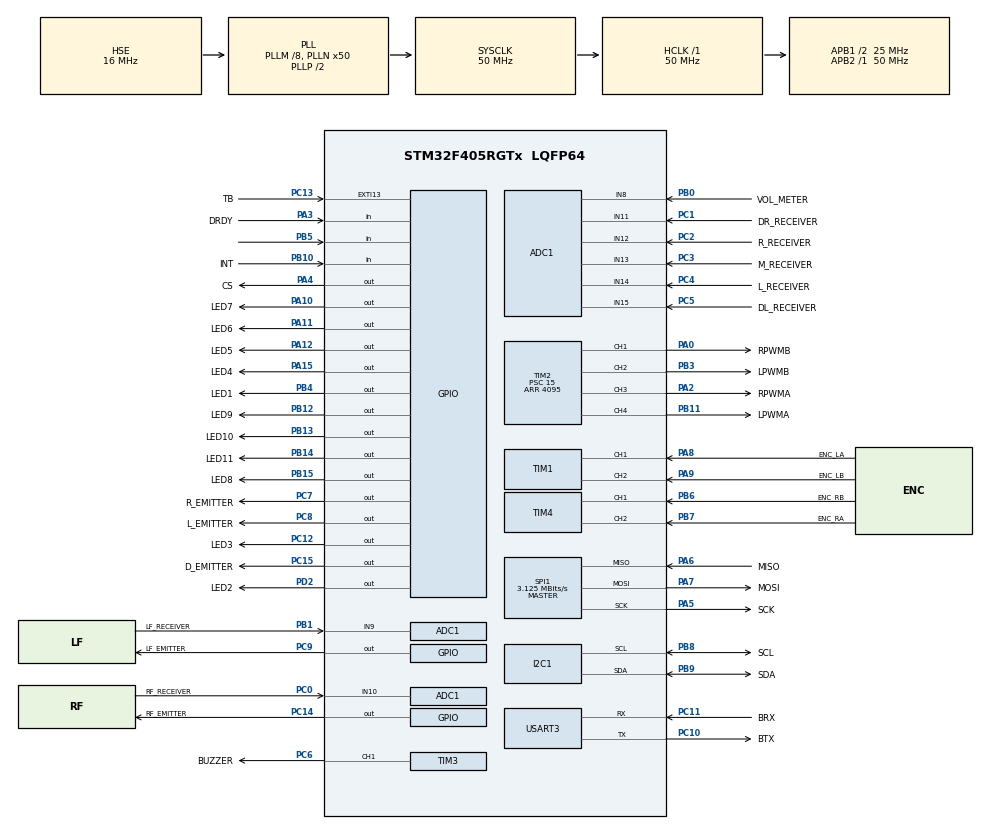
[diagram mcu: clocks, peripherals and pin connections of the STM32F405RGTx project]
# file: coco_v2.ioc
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ADC1.Channel-1\#ChannelRegularConversion=ADC_CHANNEL_10
ADC1.NbrOfConversionFlag=1
ADC1.Rank-1\#ChannelRegularConversion=1
ADC1.SamplingTime-1\#ChannelRegularConversion=ADC_SAMPLETIME_3CYCLES
ADC1.master=1
Dma.ADC1.0.Direction=DMA_PERIPH_TO_MEMORY
Dma.ADC1.0.FIFOMode=DMA_FIFOMODE_DISABLE
Dma.ADC1.0.Instance=DMA2_Stream0
Dma.ADC1.0.MemDataAlignment=DMA_MDATAALIGN_HALFWORD
Dma.ADC1.0.MemInc=DMA_MINC_ENABLE
Dma.ADC1.0.Mode=DMA_NORMAL
Dma.ADC1.0.PeriphDataAlignment=DMA_PDATAALIGN_HALFWORD
Dma.ADC1.0.PeriphInc=DMA_PINC_DISABLE
Dma.ADC1.0.Priority=DMA_PRIORITY_LOW
Dma.Request0=ADC1
I2C1.I2C_Mode=I2C_Fast
Mcu.Family=STM32F4
Mcu.Name=STM32F405RGTx
Mcu.Package=LQFP64
NVIC.DMA2_Stream0_IRQn=true\:0\:0\:false\:false\:true\:false\:true\:true
NVIC.EXTI15_10_IRQn=true\:0\:0\:false\:false\:true\:true\:true\:true
NVIC.PriorityGroup=NVIC_PRIORITYGROUP_4
NVIC.TIM8_UP_TIM13_IRQn=true\:0\:0\:false\:false\:true\:true\:true\:true
PA0-WKUP.GPIO_Label=RPWMB
PA0-WKUP.Signal=S_TIM2_CH1_ETR
PA10.GPIO_Label=LED7
PA10.GPIO_PuPd=GPIO_PULLDOWN
PA10.Signal=GPIO_Output
PA11.GPIO_Label=LED6
PA11.GPIO_PuPd=GPIO_PULLDOWN
PA11.Signal=GPIO_Output
PA12.GPIO_Label=LED5
PA12.GPIO_PuPd=GPIO_PULLDOWN
PA12.Signal=GPIO_Output
PA13.GPIO_Label=JTMS
PA13.Mode=Serial_Wire
PA13.Signal=SYS_JTMS-SWDIO
PA14.GPIO_Label=JTCK
PA14.Mode=Serial_Wire
PA14.Signal=SYS_JTCK-SWCLK
PA15.GPIO_Label=LED4
PA15.GPIO_PuPd=GPIO_PULLDOWN
PA15.Signal=GPIO_Output
PA2.GPIO_Label=RPWMA
PA2.Signal=S_TIM2_CH3
PA3.GPIO_Label=DRDY
PA3.Signal=GPIO_Input
PA4.GPIO_Label=CS
PA4.Signal=GPIO_Output
PA5.GPIO_Label=SCK
PA5.Mode=Full_Duplex_Master
PA5.Signal=SPI1_SCK
PA6.GPIO_Label=MISO
PA6.Mode=Full_Duplex_Master
PA6.Signal=SPI1_MISO
PA7.GPIO_Label=MOSI
PA7.Mode=Full_Duplex_Master
PA7.Signal=SPI1_MOSI
PA8.GPIO_Label=ENC_LA
PA8.Signal=S_TIM1_CH1
PA9.GPIO_Label=ENC_LB
PA9.Signal=S_TIM1_CH2
PB0.GPIO_Label=VOL_METER
PB0.Signal=ADCx_IN8
PB1.GPIO_Label=LF_RECEIVER
PB1.Signal=ADCx_IN9
PB10.GPIO_Label=INT
PB10.Signal=GPIO_Input
PB11.GPIO_Label=LPWMA
PB11.Signal=S_TIM2_CH4
PB12.GPIO_Label=LED9
PB12.GPIO_PuPd=GPIO_PULLDOWN
PB12.Signal=GPIO_Output
PB13.GPIO_Label=LED10
PB13.GPIO_PuPd=GPIO_PULLDOWN
PB13.Signal=GPIO_Output
PB14.GPIO_Label=LED11
PB14.GPIO_PuPd=GPIO_PULLDOWN
PB14.Signal=GPIO_Output
PB15.GPIO_Label=LED8
PB15.GPIO_ModeDefaultOutputPP=GPIO_MODE_OUTPUT_PP
PB15.GPIO_PuPd=GPIO_PULLDOWN
PB15.Signal=GPIO_Output
PB3.GPIO_Label=LPWMB
PB3.Signal=S_TIM2_CH2
PB4.GPIO_Label=LED1
PB4.GPIO_PuPd=GPIO_PULLDOWN
PB4.Signal=GPIO_Output
PB5.Signal=GPIO_Input
PB6.GPIO_Label=ENC_RB
PB6.Signal=S_TIM4_CH1
PB7.GPIO_Label=ENC_RA
PB7.Signal=S_TIM4_CH2
PB8.GPIO_Label=SCL
PB8.Mode=I2C
PB8.Signal=I2C1_SCL
PB9.GPIO_Label=SDA
PB9.Mode=I2C
PB9.Signal=I2C1_SDA
PC0.GPIO_Label=RF_RECEIVER
PC0.Signal=ADCx_IN10
PC1.GPIO_Label=DR_RECEIVER
PC1.Signal=ADCx_IN11
PC10.GPIO_Label=BTX
PC10.Mode=Asynchronous
PC10.Signal=USART3_TX
PC11.GPIO_Label=BRX
PC11.Mode=Asynchronous
PC11.Signal=USART3_RX
PC12.GPIO_Label=LED3
PC12.GPIO_PuPd=GPIO_PULLDOWN
PC12.Signal=GPIO_Output
PC13-ANTI_TAMP.GPIO_Label=TB
PC13-ANTI_TAMP.GPIO_PuPd=GPIO_PULLDOWN
PC13-ANTI_TAMP.Signal=GPXTI13
PC14-OSC32_IN.GPIO_Label=RF_EMITTER
PC14-OSC32_IN.Signal=GPIO_Output
PC15-OSC32_OUT.GPIO_Label=D_EMITTER
PC15-OSC32_OUT.Signal=GPIO_Output
PC2.GPIO_Label=R_RECEIVER
PC2.Signal=ADCx_IN12
PC3.GPIO_Label=M_RECEIVER
PC3.Signal=ADCx_IN13
PC4.GPIO_Label=L_RECEIVER
PC4.Signal=ADCx_IN14
PC5.GPIO_Label=DL_RECEIVER
PC5.Signal=ADCx_IN15
PC6.GPIO_Label=BUZZER
PC6.Signal=S_TIM3_CH1
PC7.GPIO_Label=R_EMITTER
PC7.Signal=GPIO_Output
PC8.GPIO_Label=L_EMITTER
PC8.Signal=GPIO_Output
PC9.GPIO_Label=LF_EMITTER
PC9.Signal=GPIO_Output
PD2.GPIO_Label=LED2
PD2.GPIO_PuPd=GPIO_PULLDOWN
PD2.Signal=GPIO_Output
PH0-OSC_IN.Mode=HSE-External-Oscillator
PH0-OSC_IN.Signal=RCC_OSC_IN
PH1-OSC_OUT.Mode=HSE-External-Oscillator
PH1-OSC_OUT.Signal=RCC_OSC_OUT
ProjectManager.HeapSize=0x200
ProjectManager.StackSize=0x400
ProjectManager.TargetToolchain=STM32CubeIDE
RCC.48MHZClocksFreq_Value=25000000
RCC.AHBFreq_Value=50000000
RCC.APB1CLKDivider=RCC_HCLK_DIV2
RCC.APB1Freq_Value=25000000
RCC.APB1TimFreq_Value=50000000
RCC.APB2Freq_Value=50000000
RCC.APB2TimFreq_Value=50000000
RCC.CortexFreq_Value=50000000
RCC.HCLKFreq_Value=50000000
RCC.HSE_VALUE=16000000
RCC.HSI_VALUE=16000000
RCC.LSE_VALUE=32768
RCC.PLLM=8
RCC.PLLN=50
RCC.PLLSourceVirtual=RCC_PLLSOURCE_HSE
RCC.SYSCLKFreq_VALUE=50000000
RCC.SYSCLKSource=RCC_SYSCLKSOURCE_PLLCLK
RCC.VCOOutputFreq_Value=100000000
SH.ADCx_IN10.0=ADC1_IN10,IN10
SH.ADCx_IN11.0=ADC1_IN11,IN11
SH.ADCx_IN12.0=ADC1_IN12,IN12
SH.ADCx_IN13.0=ADC1_IN13,IN13
SH.ADCx_IN14.0=ADC1_IN14,IN14
SH.ADCx_IN15.0=ADC1_IN15,IN15
SH.ADCx_IN8.0=ADC1_IN8,IN8
SH.ADCx_IN9.0=ADC1_IN9,IN9
SH.S_TIM1_CH1.0=TIM1_CH1,Encoder_Interface
SH.S_TIM1_CH2.0=TIM1_CH2,Encoder_Interface
SH.S_TIM2_CH1_ETR.0=TIM2_CH1,PWM Generation1 CH1
SH.S_TIM2_CH2.0=TIM2_CH2,PWM Generation2 CH2
SH.S_TIM2_CH3.0=TIM2_CH3,PWM Generation3 CH3
SH.S_TIM2_CH4.0=TIM2_CH4,PWM Generation4 CH4
SH.S_TIM3_CH1.0=TIM3_CH1,PWM Generation1 CH1
SH.S_TIM4_CH1.0=TIM4_CH1,Encoder_Interface
SH.S_TIM4_CH2.0=TIM4_CH2,Encoder_Interface
SPI1.BaudRatePrescaler=SPI_BAUDRATEPRESCALER_16
SPI1.CalculateBaudRate=3.125 MBits/s
SPI1.Direction=SPI_DIRECTION_2LINES
SPI1.Mode=SPI_MODE_MASTER
SPI1.VirtualType=VM_MASTER
TIM1.AutoReloadPreload=TIM_AUTORELOAD_PRELOAD_ENABLE
TIM13.Period=50000
TIM13.Prescaler=0
TIM2.AutoReloadPreload=TIM_AUTORELOAD_PRELOAD_DISABLE
TIM2.Channel-PWM\ Generation1\ CH1=TIM_CHANNEL_1
TIM2.Channel-PWM\ Generation2\ CH2=TIM_CHANNEL_2
TIM2.Channel-PWM\ Generation3\ CH3=TIM_CHANNEL_3
TIM2.Channel-PWM\ Generation4\ CH4=TIM_CHANNEL_4
TIM2.Period=4095
TIM2.Prescaler=15
TIM3.Channel-PWM\ Generation1\ CH1=TIM_CHANNEL_1
TIM3.Period=1000
TIM3.Prescaler=18
TIM4.AutoReloadPreload=TIM_AUTORELOAD_PRELOAD_ENABLE
TIM4.EncoderMode=TIM_ENCODERMODE_TI2
TIM5.Period=0xffff-1
TIM5.Prescaler=49
USART3.VirtualMode=VM_ASYNC
VP_TIM13_VS_ClockSourceINT.Mode=Enable_Timer
VP_TIM2_VS_ClockSourceINT.Mode=Internal
VP_TIM3_VS_ClockSourceINT.Mode=Internal
VP_TIM5_VS_ClockSourceINT.Mode=Internal
board=custom

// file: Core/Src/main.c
/* USER CODE BEGIN Header */
/**
  ******************************************************************************
  * @file           : main.c
  * @brief          : Main program body
  ******************************************************************************
  * @attention
  *
  * Copyright (c) 2024 STMicroelectronics.
  * All rights reserved.
  *
  * This software is licensed under terms that can be found in the LICENSE file
  * in the root directory of this software component.
  * If no LICENSE file comes with this software, it is provided AS-IS.
  *
  ******************************************************************************
  */
/* USER CODE END Header */
#include "main.h"

/* USER CODE BEGIN Includes */
#include "main.h"
#define ITM_Port32(n) (*((volatile unsigned long *)(0xE0000000+4*n)))
/* USER CODE END Includes */

ADC_HandleTypeDef hadc1;
DMA_HandleTypeDef hdma_adc1;

I2C_HandleTypeDef hi2c1;

SPI_HandleTypeDef hspi1;

TIM_HandleTypeDef htim1;
TIM_HandleTypeDef htim2;
TIM_HandleTypeDef htim3;
TIM_HandleTypeDef htim4;
TIM_HandleTypeDef htim5;
TIM_HandleTypeDef htim13;

UART_HandleTypeDef huart3;

void SystemClock_Config(void);
static void MX_GPIO_Init(void);
static void MX_DMA_Init(void);
static void MX_SPI1_Init(void);
static void MX_ADC1_Init(void);
static void MX_I2C1_Init(void);
static void MX_TIM1_Init(void);
static void MX_TIM2_Init(void);
static void MX_TIM3_Init(void);
static void MX_TIM4_Init(void);
static void MX_USART3_UART_Init(void);
static void MX_TIM5_Init(void);
static void MX_TIM13_Init(void);

int main(void)
{

  /* MCU Configuration--------------------------------------------------------*/

  /* Reset of all peripherals, Initializes the Flash interface and the Systick. */

	HAL_Init();

  /* USER CODE BEGIN Init */
//  uint32_t left_pos;
//  uint32_t right_pos;
  /* USER CODE END Init */

  /* Configure the system clock */
  SystemClock_Config();

  /* USER CODE BEGIN SysInit */
  ITM_Port32(31) = 1;
  /* USER CODE END SysInit */

  /* Initialize all configured peripherals */
  MX_GPIO_Init();
  MX_DMA_Init();
  MX_SPI1_Init();
  MX_ADC1_Init();
  MX_I2C1_Init();
  MX_TIM1_Init();
  MX_TIM2_Init();
  MX_TIM3_Init();
  MX_TIM4_Init();
  MX_USART3_UART_Init();
  MX_TIM5_Init();
  MX_TIM13_Init();
  /* USER CODE BEGIN 2 */
  ITM_Port32(31) = 2;
  cppmain();
  /* USER CODE END 2 */

  /* Infinite loop */
  while (1)
  {

  }
}

void SystemClock_Config(void)
{
  RCC_OscInitTypeDef RCC_OscInitStruct = {0};
  RCC_ClkInitTypeDef RCC_ClkInitStruct = {0};

  /** Configure the main internal regulator output voltage
  */
  __HAL_RCC_PWR_CLK_ENABLE();
  __HAL_PWR_VOLTAGESCALING_CONFIG(PWR_REGULATOR_VOLTAGE_SCALE1);

  /** Initializes the RCC Oscillators according to the specified parameters
  * in the RCC_OscInitTypeDef structure.
  */
  RCC_OscInitStruct.OscillatorType = RCC_OSCILLATORTYPE_HSE;
  RCC_OscInitStruct.HSEState = RCC_HSE_ON;
  RCC_OscInitStruct.PLL.PLLState = RCC_PLL_ON;
  RCC_OscInitStruct.PLL.PLLSource = RCC_PLLSOURCE_HSE;
  RCC_OscInitStruct.PLL.PLLM = 8;
  RCC_OscInitStruct.PLL.PLLN = 50;
  RCC_OscInitStruct.PLL.PLLP = RCC_PLLP_DIV2;
  RCC_OscInitStruct.PLL.PLLQ = 4;
  if (HAL_RCC_OscConfig(&RCC_OscInitStruct) != HAL_OK)
  {
    Error_Handler();
  }

  /** Initializes the CPU, AHB and APB buses clocks
  */
  RCC_ClkInitStruct.ClockType = RCC_CLOCKTYPE_HCLK|RCC_CLOCKTYPE_SYSCLK
                              |RCC_CLOCKTYPE_PCLK1|RCC_CLOCKTYPE_PCLK2;
  RCC_ClkInitStruct.SYSCLKSource = RCC_SYSCLKSOURCE_PLLCLK;
  RCC_ClkInitStruct.AHBCLKDivider = RCC_SYSCLK_DIV1;
  RCC_ClkInitStruct.APB1CLKDivider = RCC_HCLK_DIV2;
  RCC_ClkInitStruct.APB2CLKDivider = RCC_HCLK_DIV1;

  if (HAL_RCC_ClockConfig(&RCC_ClkInitStruct, FLASH_LATENCY_1) != HAL_OK)
  {
    Error_Handler();
  }
}

static void MX_ADC1_Init(void)
{

  ADC_ChannelConfTypeDef sConfig = {0};

  /** Configure the global features of the ADC (Clock, Resolution, Data Alignment and number of conversion)
  */
  hadc1.Instance = ADC1;
  hadc1.Init.ClockPrescaler = ADC_CLOCK_SYNC_PCLK_DIV2;
  hadc1.Init.Resolution = ADC_RESOLUTION_12B;
  hadc1.Init.ScanConvMode = DISABLE;
  hadc1.Init.ContinuousConvMode = DISABLE;
  hadc1.Init.DiscontinuousConvMode = DISABLE;
  hadc1.Init.ExternalTrigConvEdge = ADC_EXTERNALTRIGCONVEDGE_NONE;
  hadc1.Init.ExternalTrigConv = ADC_SOFTWARE_START;
  hadc1.Init.DataAlign = ADC_DATAALIGN_RIGHT;
  hadc1.Init.NbrOfConversion = 1;
  hadc1.Init.DMAContinuousRequests = DISABLE;
  hadc1.Init.EOCSelection = ADC_EOC_SINGLE_CONV;
  if (HAL_ADC_Init(&hadc1) != HAL_OK)
  {
    Error_Handler();
  }

  /** Configure for the selected ADC regular channel its corresponding rank in the sequencer and its sample time.
  */
  sConfig.Channel = ADC_CHANNEL_10;
  sConfig.Rank = 1;
  sConfig.SamplingTime = ADC_SAMPLETIME_3CYCLES;
  if (HAL_ADC_ConfigChannel(&hadc1, &sConfig) != HAL_OK)
  {
    Error_Handler();
  }

}

static void MX_I2C1_Init(void)
{

  hi2c1.Instance = I2C1;
  hi2c1.Init.ClockSpeed = 400000;
  hi2c1.Init.DutyCycle = I2C_DUTYCYCLE_2;
  hi2c1.Init.OwnAddress1 = 0;
  hi2c1.Init.AddressingMode = I2C_ADDRESSINGMODE_7BIT;
  hi2c1.Init.DualAddressMode = I2C_DUALADDRESS_DISABLE;
  hi2c1.Init.OwnAddress2 = 0;
  hi2c1.Init.GeneralCallMode = I2C_GENERALCALL_DISABLE;
  hi2c1.Init.NoStretchMode = I2C_NOSTRETCH_DISABLE;
  if (HAL_I2C_Init(&hi2c1) != HAL_OK)
  {
    Error_Handler();
  }

}

static void MX_SPI1_Init(void)
{

  /* SPI1 parameter configuration*/
  hspi1.Instance = SPI1;
  hspi1.Init.Mode = SPI_MODE_MASTER;
  hspi1.Init.Direction = SPI_DIRECTION_2LINES;
  hspi1.Init.DataSize = SPI_DATASIZE_8BIT;
  hspi1.Init.CLKPolarity = SPI_POLARITY_LOW;
  hspi1.Init.CLKPhase = SPI_PHASE_1EDGE;
  hspi1.Init.NSS = SPI_NSS_SOFT;
  hspi1.Init.BaudRatePrescaler = SPI_BAUDRATEPRESCALER_16;
  hspi1.Init.FirstBit = SPI_FIRSTBIT_MSB;
  hspi1.Init.TIMode = SPI_TIMODE_DISABLE;
  hspi1.Init.CRCCalculation = SPI_CRCCALCULATION_DISABLE;
  hspi1.Init.CRCPolynomial = 10;
  if (HAL_SPI_Init(&hspi1) != HAL_OK)
  {
    Error_Handler();
  }

}

static void MX_TIM1_Init(void)
{

  TIM_Encoder_InitTypeDef sConfig = {0};
  TIM_MasterConfigTypeDef sMasterConfig = {0};

  htim1.Instance = TIM1;
  htim1.Init.Prescaler = 0;
  htim1.Init.CounterMode = TIM_COUNTERMODE_UP;
  htim1.Init.Period = 65535;
  htim1.Init.ClockDivision = TIM_CLOCKDIVISION_DIV1;
  htim1.Init.RepetitionCounter = 0;
  htim1.Init.AutoReloadPreload = TIM_AUTORELOAD_PRELOAD_ENABLE;
  sConfig.EncoderMode = TIM_ENCODERMODE_TI1;
  sConfig.IC1Polarity = TIM_ICPOLARITY_RISING;
  sConfig.IC1Selection = TIM_ICSELECTION_DIRECTTI;
  sConfig.IC1Prescaler = TIM_ICPSC_DIV1;
  sConfig.IC1Filter = 0;
  sConfig.IC2Polarity = TIM_ICPOLARITY_RISING;
  sConfig.IC2Selection = TIM_ICSELECTION_DIRECTTI;
  sConfig.IC2Prescaler = TIM_ICPSC_DIV1;
  sConfig.IC2Filter = 0;
  if (HAL_TIM_Encoder_Init(&htim1, &sConfig) != HAL_OK)
  {
    Error_Handler();
  }
  sMasterConfig.MasterOutputTrigger = TIM_TRGO_RESET;
  sMasterConfig.MasterSlaveMode = TIM_MASTERSLAVEMODE_DISABLE;
  if (HAL_TIMEx_MasterConfigSynchronization(&htim1, &sMasterConfig) != HAL_OK)
  {
    Error_Handler();
  }

}

static void MX_TIM2_Init(void)
{

  TIM_ClockConfigTypeDef sClockSourceConfig = {0};
  TIM_MasterConfigTypeDef sMasterConfig = {0};
  TIM_OC_InitTypeDef sConfigOC = {0};

  htim2.Instance = TIM2;
  htim2.Init.Prescaler = 15;
  htim2.Init.CounterMode = TIM_COUNTERMODE_UP;
  htim2.Init.Period = 4095;
  htim2.Init.ClockDivision = TIM_CLOCKDIVISION_DIV1;
  htim2.Init.AutoReloadPreload = TIM_AUTORELOAD_PRELOAD_DISABLE;
  if (HAL_TIM_Base_Init(&htim2) != HAL_OK)
  {
    Error_Handler();
  }
  sClockSourceConfig.ClockSource = TIM_CLOCKSOURCE_INTERNAL;
  if (HAL_TIM_ConfigClockSource(&htim2, &sClockSourceConfig) != HAL_OK)
  {
    Error_Handler();
  }
  if (HAL_TIM_PWM_Init(&htim2) != HAL_OK)
  {
    Error_Handler();
  }
  sMasterConfig.MasterOutputTrigger = TIM_TRGO_RESET;
  sMasterConfig.MasterSlaveMode = TIM_MASTERSLAVEMODE_DISABLE;
  if (HAL_TIMEx_MasterConfigSynchronization(&htim2, &sMasterConfig) != HAL_OK)
  {
    Error_Handler();
  }
  sConfigOC.OCMode = TIM_OCMODE_PWM1;
  sConfigOC.Pulse = 0;
  sConfigOC.OCPolarity = TIM_OCPOLARITY_HIGH;
  sConfigOC.OCFastMode = TIM_OCFAST_DISABLE;
  if (HAL_TIM_PWM_ConfigChannel(&htim2, &sConfigOC, TIM_CHANNEL_1) != HAL_OK)
  {
    Error_Handler();
  }
  if (HAL_TIM_PWM_ConfigChannel(&htim2, &sConfigOC, TIM_CHANNEL_2) != HAL_OK)
  {
    Error_Handler();
  }
  if (HAL_TIM_PWM_ConfigChannel(&htim2, &sConfigOC, TIM_CHANNEL_3) != HAL_OK)
  {
    Error_Handler();
  }
  if (HAL_TIM_PWM_ConfigChannel(&htim2, &sConfigOC, TIM_CHANNEL_4) != HAL_OK)
  {
    Error_Handler();
  }
  HAL_TIM_MspPostInit(&htim2);

}

static void MX_TIM3_Init(void)
{

  TIM_ClockConfigTypeDef sClockSourceConfig = {0};
  TIM_MasterConfigTypeDef sMasterConfig = {0};
  TIM_OC_InitTypeDef sConfigOC = {0};

  htim3.Instance = TIM3;
  htim3.Init.Prescaler = 18;
  htim3.Init.CounterMode = TIM_COUNTERMODE_UP;
  htim3.Init.Period = 1000;
  htim3.Init.ClockDivision = TIM_CLOCKDIVISION_DIV1;
  htim3.Init.AutoReloadPreload = TIM_AUTORELOAD_PRELOAD_DISABLE;
  if (HAL_TIM_Base_Init(&htim3) != HAL_OK)
  {
    Error_Handler();
  }
  sClockSourceConfig.ClockSource = TIM_CLOCKSOURCE_INTERNAL;
  if (HAL_TIM_ConfigClockSource(&htim3, &sClockSourceConfig) != HAL_OK)
  {
    Error_Handler();
  }
  if (HAL_TIM_PWM_Init(&htim3) != HAL_OK)
  {
    Error_Handler();
  }
  sMasterConfig.MasterOutputTrigger = TIM_TRGO_RESET;
  sMasterConfig.MasterSlaveMode = TIM_MASTERSLAVEMODE_DISABLE;
  if (HAL_TIMEx_MasterConfigSynchronization(&htim3, &sMasterConfig) != HAL_OK)
  {
    Error_Handler();
  }
  sConfigOC.OCMode = TIM_OCMODE_PWM1;
  sConfigOC.Pulse = 0;
  sConfigOC.OCPolarity = TIM_OCPOLARITY_HIGH;
  sConfigOC.OCFastMode = TIM_OCFAST_DISABLE;
  if (HAL_TIM_PWM_ConfigChannel(&htim3, &sConfigOC, TIM_CHANNEL_1) != HAL_OK)
  {
    Error_Handler();
  }
  HAL_TIM_MspPostInit(&htim3);

}

static void MX_TIM4_Init(void)
{

  TIM_Encoder_InitTypeDef sConfig = {0};
  TIM_MasterConfigTypeDef sMasterConfig = {0};

  htim4.Instance = TIM4;
  htim4.Init.Prescaler = 0;
  htim4.Init.CounterMode = TIM_COUNTERMODE_UP;
  htim4.Init.Period = 65535;
  htim4.Init.ClockDivision = TIM_CLOCKDIVISION_DIV1;
  htim4.Init.AutoReloadPreload = TIM_AUTORELOAD_PRELOAD_ENABLE;
  sConfig.EncoderMode = TIM_ENCODERMODE_TI2;
  sConfig.IC1Polarity = TIM_ICPOLARITY_RISING;
  sConfig.IC1Selection = TIM_ICSELECTION_DIRECTTI;
  sConfig.IC1Prescaler = TIM_ICPSC_DIV1;
  sConfig.IC1Filter = 0;
  sConfig.IC2Polarity = TIM_ICPOLARITY_RISING;
  sConfig.IC2Selection = TIM_ICSELECTION_DIRECTTI;
  sConfig.IC2Prescaler = TIM_ICPSC_DIV1;
  sConfig.IC2Filter = 0;
  if (HAL_TIM_Encoder_Init(&htim4, &sConfig) != HAL_OK)
  {
    Error_Handler();
  }
  sMasterConfig.MasterOutputTrigger = TIM_TRGO_RESET;
  sMasterConfig.MasterSlaveMode = TIM_MASTERSLAVEMODE_DISABLE;
  if (HAL_TIMEx_MasterConfigSynchronization(&htim4, &sMasterConfig) != HAL_OK)
  {
    Error_Handler();
  }

}

static void MX_TIM5_Init(void)
{

  TIM_ClockConfigTypeDef sClockSourceConfig = {0};
  TIM_MasterConfigTypeDef sMasterConfig = {0};

  htim5.Instance = TIM5;
  htim5.Init.Prescaler = 49;
  htim5.Init.CounterMode = TIM_COUNTERMODE_UP;
  htim5.Init.Period = 0xffff-1;
  htim5.Init.ClockDivision = TIM_CLOCKDIVISION_DIV1;
  htim5.Init.AutoReloadPreload = TIM_AUTORELOAD_PRELOAD_DISABLE;
  if (HAL_TIM_Base_Init(&htim5) != HAL_OK)
  {
    Error_Handler();
  }
  sClockSourceConfig.ClockSource = TIM_CLOCKSOURCE_INTERNAL;
  if (HAL_TIM_ConfigClockSource(&htim5, &sClockSourceConfig) != HAL_OK)
  {
    Error_Handler();
  }
  sMasterConfig.MasterOutputTrigger = TIM_TRGO_RESET;
  sMasterConfig.MasterSlaveMode = TIM_MASTERSLAVEMODE_DISABLE;
  if (HAL_TIMEx_MasterConfigSynchronization(&htim5, &sMasterConfig) != HAL_OK)
  {
    Error_Handler();
  }

}

static void MX_TIM13_Init(void)
{

  htim13.Instance = TIM13;
  htim13.Init.Prescaler = 0;
  htim13.Init.CounterMode = TIM_COUNTERMODE_UP;
  htim13.Init.Period = 50000;
  htim13.Init.ClockDivision = TIM_CLOCKDIVISION_DIV1;
  htim13.Init.AutoReloadPreload = TIM_AUTORELOAD_PRELOAD_DISABLE;
  if (HAL_TIM_Base_Init(&htim13) != HAL_OK)
  {
    Error_Handler();
  }

}

static void MX_USART3_UART_Init(void)
{

  huart3.Instance = USART3;
  huart3.Init.BaudRate = 115200;
  huart3.Init.WordLength = UART_WORDLENGTH_8B;
  huart3.Init.StopBits = UART_STOPBITS_1;
  huart3.Init.Parity = UART_PARITY_NONE;
  huart3.Init.Mode = UART_MODE_TX_RX;
  huart3.Init.HwFlowCtl = UART_HWCONTROL_NONE;
  huart3.Init.OverSampling = UART_OVERSAMPLING_16;
  if (HAL_UART_Init(&huart3) != HAL_OK)
  {
    Error_Handler();
  }

}

static void MX_DMA_Init(void)
{

  /* DMA controller clock enable */
  __HAL_RCC_DMA2_CLK_ENABLE();

  /* DMA interrupt init */
  /* DMA2_Stream0_IRQn interrupt configuration */
  HAL_NVIC_SetPriority(DMA2_Stream0_IRQn, 0, 0);
  HAL_NVIC_EnableIRQ(DMA2_Stream0_IRQn);

}

static void MX_GPIO_Init(void)
{
  GPIO_InitTypeDef GPIO_InitStruct = {0};

  /* GPIO Ports Clock Enable */
  __HAL_RCC_GPIOC_CLK_ENABLE();
  __HAL_RCC_GPIOH_CLK_ENABLE();
  __HAL_RCC_GPIOA_CLK_ENABLE();
  __HAL_RCC_GPIOB_CLK_ENABLE();
  __HAL_RCC_GPIOD_CLK_ENABLE();

  /*Configure GPIO pin Output Level */
  HAL_GPIO_WritePin(GPIOC, RF_EMITTER_Pin|D_EMITTER_Pin|R_EMITTER_Pin|L_EMITTER_Pin
                          |LF_EMITTER_Pin|LED3_Pin, GPIO_PIN_RESET);

  /*Configure GPIO pin Output Level */
  HAL_GPIO_WritePin(GPIOA, CS_Pin|LED7_Pin|LED6_Pin|LED5_Pin
                          |LED4_Pin, GPIO_PIN_RESET);

  /*Configure GPIO pin Output Level */
  HAL_GPIO_WritePin(GPIOB, LED9_Pin|LED10_Pin|LED11_Pin|LED8_Pin
                          |LED1_Pin, GPIO_PIN_RESET);

  /*Configure GPIO pin Output Level */
  HAL_GPIO_WritePin(LED2_GPIO_Port, LED2_Pin, GPIO_PIN_RESET);

  /*Configure GPIO pin : TB_Pin */
  GPIO_InitStruct.Pin = TB_Pin;
  GPIO_InitStruct.Mode = GPIO_MODE_IT_RISING;
  GPIO_InitStruct.Pull = GPIO_PULLDOWN;
  HAL_GPIO_Init(TB_GPIO_Port, &GPIO_InitStruct);

  /*Configure GPIO pins : RF_EMITTER_Pin D_EMITTER_Pin R_EMITTER_Pin L_EMITTER_Pin
                           LF_EMITTER_Pin */
  GPIO_InitStruct.Pin = RF_EMITTER_Pin|D_EMITTER_Pin|R_EMITTER_Pin|L_EMITTER_Pin
                          |LF_EMITTER_Pin;
  GPIO_InitStruct.Mode = GPIO_MODE_OUTPUT_PP;
  GPIO_InitStruct.Pull = GPIO_NOPULL;
  GPIO_InitStruct.Speed = GPIO_SPEED_FREQ_LOW;
  HAL_GPIO_Init(GPIOC, &GPIO_InitStruct);

  /*Configure GPIO pin : DRDY_Pin */
  GPIO_InitStruct.Pin = DRDY_Pin;
  GPIO_InitStruct.Mode = GPIO_MODE_INPUT;
  GPIO_InitStruct.Pull = GPIO_NOPULL;
  HAL_GPIO_Init(DRDY_GPIO_Port, &GPIO_InitStruct);

  /*Configure GPIO pin : CS_Pin */
  GPIO_InitStruct.Pin = CS_Pin;
  GPIO_InitStruct.Mode = GPIO_MODE_OUTPUT_PP;
  GPIO_InitStruct.Pull = GPIO_NOPULL;
  GPIO_InitStruct.Speed = GPIO_SPEED_FREQ_LOW;
  HAL_GPIO_Init(CS_GPIO_Port, &GPIO_InitStruct);

  /*Configure GPIO pins : INT_Pin PB5 */
  GPIO_InitStruct.Pin = INT_Pin|GPIO_PIN_5;
  GPIO_InitStruct.Mode = GPIO_MODE_INPUT;
  GPIO_InitStruct.Pull = GPIO_NOPULL;
  HAL_GPIO_Init(GPIOB, &GPIO_InitStruct);

  /*Configure GPIO pins : LED9_Pin LED10_Pin LED11_Pin LED8_Pin
                           LED1_Pin */
  GPIO_InitStruct.Pin = LED9_Pin|LED10_Pin|LED11_Pin|LED8_Pin
                          |LED1_Pin;
  GPIO_InitStruct.Mode = GPIO_MODE_OUTPUT_PP;
  GPIO_InitStruct.Pull = GPIO_PULLDOWN;
  GPIO_InitStruct.Speed = GPIO_SPEED_FREQ_LOW;
  HAL_GPIO_Init(GPIOB, &GPIO_InitStruct);

  /*Configure GPIO pins : LED7_Pin LED6_Pin LED5_Pin LED4_Pin */
  GPIO_InitStruct.Pin = LED7_Pin|LED6_Pin|LED5_Pin|LED4_Pin;
  GPIO_InitStruct.Mode = GPIO_MODE_OUTPUT_PP;
  GPIO_InitStruct.Pull = GPIO_PULLDOWN;
  GPIO_InitStruct.Speed = GPIO_SPEED_FREQ_LOW;
  HAL_GPIO_Init(GPIOA, &GPIO_InitStruct);

  /*Configure GPIO pin : LED3_Pin */
  GPIO_InitStruct.Pin = LED3_Pin;
  GPIO_InitStruct.Mode = GPIO_MODE_OUTPUT_PP;
  GPIO_InitStruct.Pull = GPIO_PULLDOWN;
  GPIO_InitStruct.Speed = GPIO_SPEED_FREQ_LOW;
  HAL_GPIO_Init(LED3_GPIO_Port, &GPIO_InitStruct);

  /*Configure GPIO pin : LED2_Pin */
  GPIO_InitStruct.Pin = LED2_Pin;
  GPIO_InitStruct.Mode = GPIO_MODE_OUTPUT_PP;
  GPIO_InitStruct.Pull = GPIO_PULLDOWN;
  GPIO_InitStruct.Speed = GPIO_SPEED_FREQ_LOW;
  HAL_GPIO_Init(LED2_GPIO_Port, &GPIO_InitStruct);

  /* EXTI interrupt init*/
  HAL_NVIC_SetPriority(EXTI15_10_IRQn, 0, 0);
  HAL_NVIC_EnableIRQ(EXTI15_10_IRQn);

}

void Error_Handler(void)
{
  __disable_irq();
  while (1)
  {
  }
}
